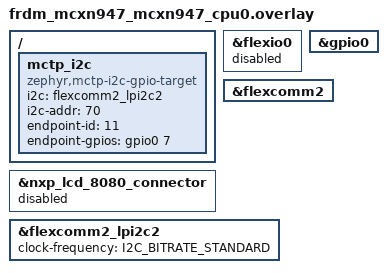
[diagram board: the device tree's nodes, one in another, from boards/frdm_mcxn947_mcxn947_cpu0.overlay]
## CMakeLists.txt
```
cmake_minimum_required(VERSION 3.28.0)

find_package(Zephyr REQUIRED HINTS $ENV{ZEPHYR_BASE})
project(mctp_i2c_gpio_bus_endpoint)

target_sources(app PRIVATE src/main.c)
```

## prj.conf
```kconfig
CONFIG_I2C=y
CONFIG_I2C_TARGET=y
CONFIG_MCTP=y
CONFIG_MCTP_I2C_GPIO_TARGET=y
CONFIG_LOG=y
CONFIG_LOG_BUFFER_SIZE=4096
```

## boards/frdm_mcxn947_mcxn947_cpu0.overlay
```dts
#include <zephyr/dt-bindings/gpio/gpio.h>

/* Sets up I2C and a GPIO on JP8 to use as our i2c bus for MCTP.
 * SDA: J2.18
 * SCL: J2.20
 * GPIO: J8.8
 * GND: J8.2
 */

&nxp_lcd_8080_connector {
	status = "disabled";
};

&flexio0 {
	status = "disabled";
};

&gpio0 {
	status = "okay";
};

&flexcomm2 {
	status = "okay";
};

&flexcomm2_lpi2c2 {
	clock-frequency = <I2C_BITRATE_STANDARD>;
	status = "okay";
};

/ {
	mctp_i2c: mctp_i2c {
		compatible = "zephyr,mctp-i2c-gpio-target";
		i2c = <&flexcomm2_lpi2c2>;
		i2c-addr = <70>;
		endpoint-id = <11>;
		endpoint-gpios = <&gpio0 7 GPIO_ACTIVE_HIGH>;
	};
};
```

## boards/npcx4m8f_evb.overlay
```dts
/*
 * Copyright (c) 2025 Intel Corporation
 *
 * SPDX-License-Identifier: Apache-2.0
 */

/ {
	/* SDA J18.2 */
	/* SCL J18.1 */
	/* GPIO J17.2 */
	mctp_i2c: mctp_i2c {
		compatible = "zephyr,mctp-i2c-gpio-target";
		i2c = <&i2c0_0>;
		i2c-addr = <70>;
		endpoint-id = <11>;
		endpoint-gpios = <&gpio4 3 GPIO_ACTIVE_HIGH>;
	};
};
```

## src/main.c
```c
/*
 * Copyright (c) 2025 Intel Corporation
 *
 * SPDX-License-Identifier: Apache-2.0
 */

#include <stdio.h>
#include <assert.h>
#include <zephyr/types.h>
#include <zephyr/kernel.h>
#include <libmctp.h>
#include <zephyr/pmci/mctp/mctp_i2c_gpio_target.h>

#include <zephyr/logging/log.h>
LOG_MODULE_REGISTER(mctp_i2c_gpio_bus_endpoint);

MCTP_I2C_GPIO_TARGET_DT_DEFINE(mctp_i2c_ctrl, DT_NODELABEL(mctp_i2c));

K_SEM_DEFINE(mctp_rx, 0, 1);

struct mctp *mctp_ctx;

#define BUS_OWNER_ID 20

static void rx_message_handler(struct k_work *work)
{
	ARG_UNUSED(work);

	mctp_message_tx(mctp_ctx, BUS_OWNER_ID, false, 0, "pong", sizeof("pong"));

	k_sem_give(&mctp_rx);
}
K_WORK_DEFINE(rx_message_work, rx_message_handler);

static void rx_message(uint8_t eid, bool tag_owner, uint8_t msg_tag, void *data, void *msg,
		       size_t len)
{
	LOG_INF("received message \"%s\" from endpoint %d, replying with \"pong\"", (char *)msg,
		eid);

	/* While small messages, such as this "pong" can be sent from the ISR context, bigger ones,
	 * which will be split into several packets by libmctp won't work. Using a work queue
	 * to send replies is thus safer for more cases.
	 */
	k_work_submit(&rx_message_work);
}

int main(void)
{
	LOG_INF("MCTP Host EID:%d on %s\n", mctp_i2c_ctrl.endpoint_id, CONFIG_BOARD_TARGET);

	mctp_ctx = mctp_init();
	__ASSERT_NO_MSG(mctp_ctx != NULL);
	mctp_register_bus(mctp_ctx, &mctp_i2c_ctrl.binding, mctp_i2c_ctrl.endpoint_id);
	mctp_set_rx_all(mctp_ctx, rx_message, NULL);

	/*
	 * MCTP poll loop, listening for messages.
	 */
	while (true) {
		k_sem_take(&mctp_rx, K_FOREVER);
	}

	return 0;
}
```
